# ATmega8 register map
File version: 1.0
Registers are 8-bit, read-write, reset 0x0 unless marked. A register's access mark holds for its fields unless they carry their own. Offsets are from the block's base; lines under a group give offsets from that group; [hi:lo] are bit positions; {n}, {i} and the like mark numbered series; 'fields as' and 'values as' point back to an identical list; <NAME> marks a mode.

## Memory map
0x00800000 AC — Analog Comparator
0x00800000 AC_2 — Analog Comparator
0x00800000 SPI — Serial Peripheral Interface
0x00800000 EXINT — External Interrupts
0x00800000 TC0 — Timer/Counter, 8-bit
0x00800000 TC1 — Timer/Counter, 16-bit
0x00800000 TC2 — Timer/Counter, 8-bit Async
0x00800000 TC2_2 — Timer/Counter, 8-bit Async
0x00800000 USART
0x00800000 USART_2 — USART
0x00800000 TWI — Two Wire Serial Interface
0x00800000 WDT — Watchdog Timer
0x00800000 PORTB — I/O Port
0x00800000 PORTC — I/O Port
0x00800000 PORTD — I/O Port
0x00800000 EEPROM
0x00800000 ADC — Analog-to-Digital Converter

## AC — Analog Comparator
Base 0x00800000
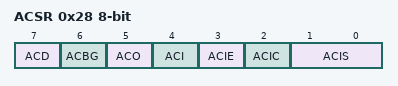
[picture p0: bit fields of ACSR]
0x28 ACSR — Analog Comparator Control And Status Register
  [7] ACD — Analog Comparator Disable
  [6] ACBG — Analog Comparator Bandgap Select
  [5] ACO — Analog Compare Output
  [4] ACI — Analog Comparator Interrupt Flag
  [3] ACIE — Analog Comparator Interrupt Enable
  [2] ACIC — Analog Comparator Input Capture Enable
  [1:0] ACIS — Analog Comparator Interrupt Mode Select bits

## AC_2 — Analog Comparator
Base 0x00800000
0x50 SFIOR — Special Function IO Register
  [3] ACME — Analog Comparator Multiplexer Enable

## SPI — Serial Peripheral Interface
Base 0x00800000
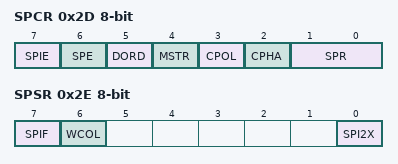
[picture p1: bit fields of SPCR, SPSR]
0x2D SPCR — SPI Control Register
  [7] SPIE — SPI Interrupt Enable
  [6] SPE — SPI Enable
  [5] DORD — Data Order
  [4] MSTR — Master/Slave Select
  [3] CPOL — Clock polarity
  [2] CPHA — Clock Phase
  [1:0] SPR — SPI Clock Rate Selects
0x2E SPSR — SPI Status Register
  [7] SPIF — SPI Interrupt Flag
  [6] WCOL — Write Collision Flag
  [0] SPI2X — Double SPI Speed Bit

## EXINT — External Interrupts
Base 0x00800000
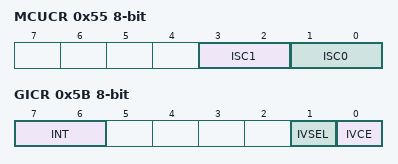
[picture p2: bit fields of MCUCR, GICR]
0x55 MCUCR — MCU Control Register
  [3:2] ISC1 — Interrupt Sense Control 1 Bits
  [1:0] ISC0 — Interrupt Sense Control 0 Bits
0x5A GIFR — General Interrupt Flag Register
  [7:6] INTF — External Interrupt Flags
0x5B GICR — General Interrupt Control Register
  [7:6] INT — External Interrupt Request 1 Enable
  [1] IVSEL — Interrupt Vector Select
  [0] IVCE — Interrupt Vector Change Enable

## TC0 — Timer/Counter, 8-bit
Base 0x00800000
0x52 TCNT0 — Timer Counter 0
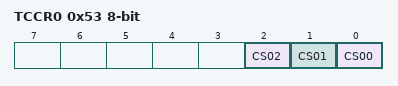
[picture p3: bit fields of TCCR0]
0x53 TCCR0 — Timer/Counter0 Control Register
  [2] CS02 — Clock Select0 bit 2
  [1] CS01 — Clock Select0 bit 1
  [0] CS00 — Clock Select0 bit 0
0x58 TIFR — Timer/Counter Interrupt Flag register
  [0] TOV0 — Timer/Counter0 Overflow Flag
0x59 TIMSK — Timer/Counter Interrupt Mask Register
  [0] TOIE0 — Timer/Counter0 Overflow Interrupt Enable

## TC1 — Timer/Counter, 16-bit
Base 0x00800000
0x46 ICR1 16-bit (reset mask 0xFF) — Timer/Counter1 Input Capture Register Bytes
0x48 OCR1B 16-bit (reset mask 0xFF) — Timer/Counter1 Output Compare Register Bytes
0x4A OCR1A 16-bit (reset mask 0xFF) — Timer/Counter1 Output Compare Register Bytes
0x4C TCNT1 16-bit (reset mask 0xFF) — Timer/Counter1 Bytes
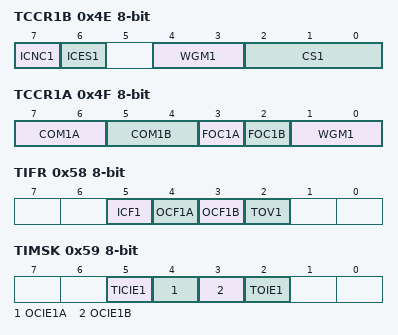
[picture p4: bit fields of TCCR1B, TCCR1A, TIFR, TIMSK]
0x4E TCCR1B — Timer/Counter1 Control Register B
  [7] ICNC1 — Input Capture 1 Noise Canceler
  [6] ICES1 — Input Capture 1 Edge Select
  [4:3] WGM1 — Waveform Generation Mode
  [2:0] CS1 — Prescaler source of Timer/Counter 1
0x4F TCCR1A — Timer/Counter1 Control Register A
  [7:6] COM1A — Compare Output Mode 1A, bits
  [5:4] COM1B — Compare Output Mode 1B, bits
  [3] FOC1A — Force Output Compare 1A
  [2] FOC1B — Force Output Compare 1B
  [1:0] WGM1 — Waveform Generation Mode
0x58 TIFR — Timer/Counter Interrupt Flag register
  [5] ICF1 — Input Capture Flag 1
  [4] OCF1A — Output Compare Flag 1A
  [3] OCF1B — Output Compare Flag 1B
  [2] TOV1 — Timer/Counter1 Overflow Flag
0x59 TIMSK — Timer/Counter Interrupt Mask Register
  [5] TICIE1 — Timer/Counter1 Input Capture Interrupt Enable
  [4] OCIE1A — Timer/Counter1 Output CompareA Match Interrupt Enable
  [3] OCIE1B — Timer/Counter1 Output CompareB Match Interrupt Enable
  [2] TOIE1 — Timer/Counter1 Overflow Interrupt Enable
